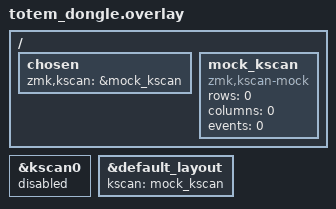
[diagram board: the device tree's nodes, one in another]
#include "totem.dtsi"
/ {
    chosen { zmk,kscan = &mock_kscan; };
    mock_kscan: mock_kscan {
        compatible = "zmk,kscan-mock";
        rows = <0>; columns = <0>; events = <0>;
    };
};
&kscan0 { status = "disabled"; };
&default_layout { kscan = <&mock_kscan>; };
